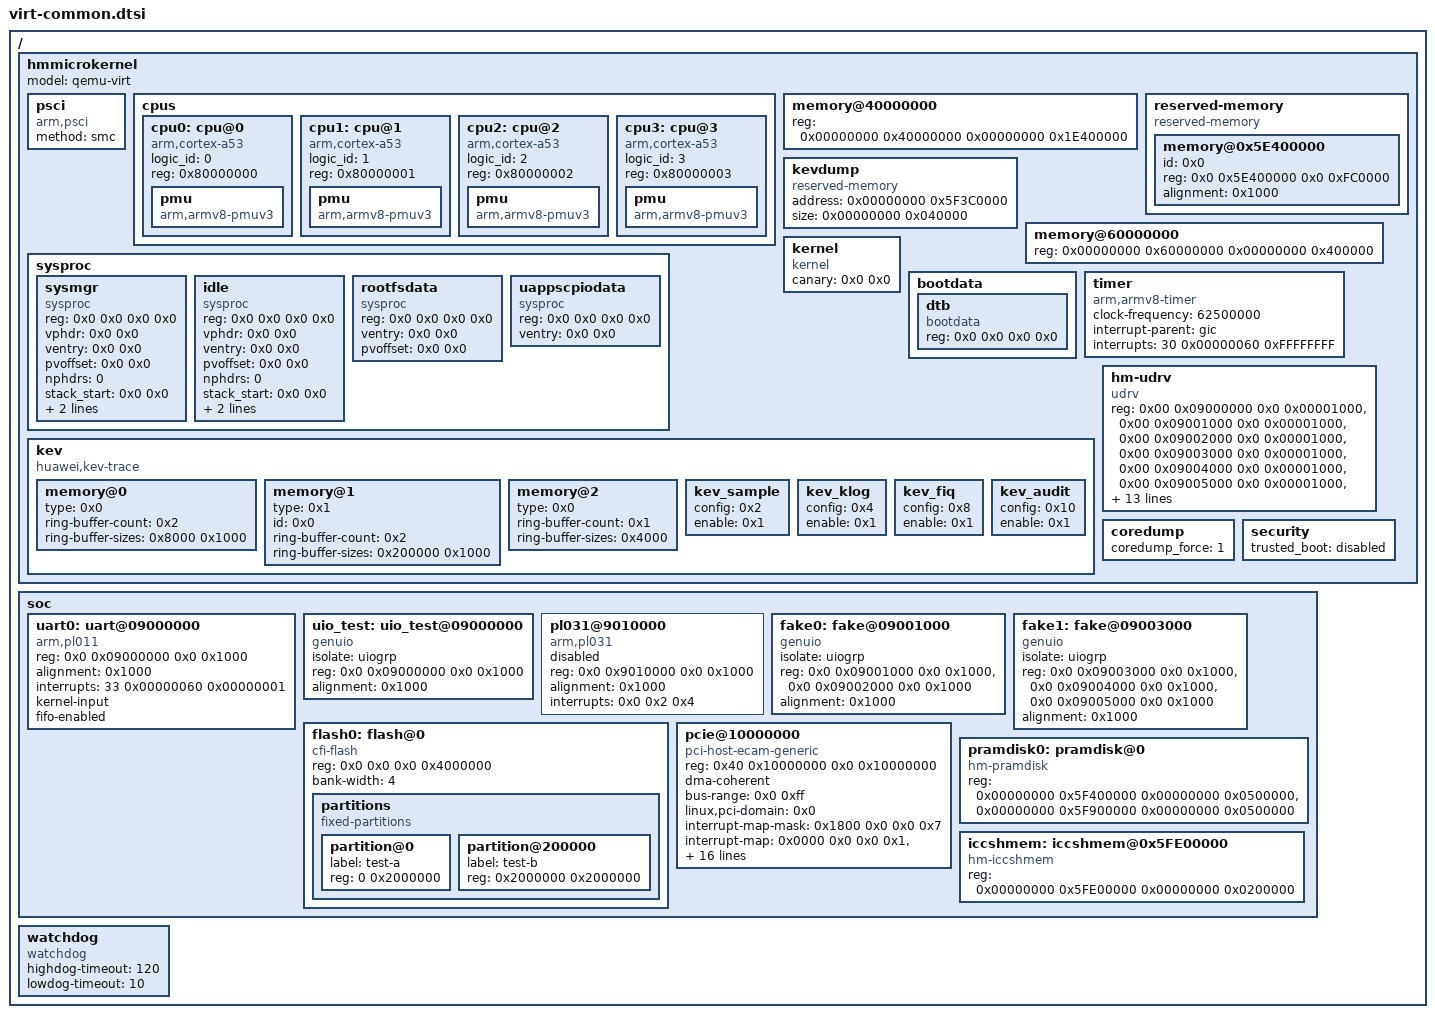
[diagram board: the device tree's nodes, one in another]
/ {
	hmmicrokernel {
		model = "qemu-virt";
		psci {
			compatible = "arm,psci";
			method = "smc";
		};

		cpus {
			#address-cells = <1>;
			#size-cells = <0>;
			cpu0: cpu@0 {
				compatible = "arm,cortex-a53", "arm,armv8";
				device_type = "cpu";
				logic_id = <0>;
				reg = <0x80000000>;
				pmu {
					compatible = "arm,armv8-pmuv3";
				};
			};
			cpu1: cpu@1 {
				compatible = "arm,cortex-a53", "arm,armv8";
				device_type = "cpu";
				logic_id = <1>;
				reg = <0x80000001>;
				pmu {
					compatible = "arm,armv8-pmuv3";
				};
			};
			cpu2: cpu@2 {
				compatible = "arm,cortex-a53", "arm,armv8";
				device_type = "cpu";
				logic_id = <2>;
				reg = <0x80000002>;
				pmu {
					compatible = "arm,armv8-pmuv3";
				};
			};
			cpu3: cpu@3 {
				compatible = "arm,cortex-a53", "arm,armv8";
				device_type = "cpu";
				logic_id = <3>;
				reg = <0x80000003>;
				pmu {
					compatible = "arm,armv8-pmuv3";
				};
			};
		};

		memory@40000000 {
			device_type = "memory";
			reg = <0x00000000 0x40000000 0x00000000 0x1E400000>;
		};

		reserved-memory {
			compatible = "reserved-memory";
			#address-cells = <2>;
			#size-cells = <2>;

			/* 16M - 256KB */
			memory@0x5E400000 {
				id = <0x0>;
				reg = <0x0 0x5E400000 0x0 0xFC0000>;
				alignment = <0x1000>;
			};
		};

		kevdump {
			compatible = "reserved-memory";
			address = <0x00000000 0x5F3C0000>;
			/* 256KB for kevdump */
			size = <0x00000000 0x040000>;
		};

		memory@60000000 {
			device_type = "memory";
			reg = <0x00000000 0x60000000 0x00000000 0x400000>;
		};

		sysproc {
			#address-cells = <2>;
			#size-cells = <2>;
			sysmgr {
				compatible = "sysproc", "sysmgr";
				/* filled by bootloader */
				reg      = <0x0 0x0 0x0 0x0>;
				vphdr    = <0x0 0x0>;
				ventry   = <0x0 0x0>;
				pvoffset = <0x0 0x0>;
				nphdrs   = <0>;
				stack_start = <0x0 0x0>;
				stack_end = <0x0 0x0>;
				canary = <0x0 0x0>;
			};
			idle {
				compatible = "sysproc", "idle";
				/* filled by bootloader */
				reg      = <0x0 0x0 0x0 0x0>;
				vphdr    = <0x0 0x0>;
				ventry   = <0x0 0x0>;
				pvoffset = <0x0 0x0>;
				nphdrs   = <0>;
				stack_start = <0x0 0x0>;
				stack_end = <0x0 0x0>;
				canary = <0x0 0x0>;
			};
			rootfsdata {
				compatible = "sysproc", "rootfs";
				/* filled by bootloader */
				reg      = <0x0 0x0 0x0 0x0>;
				ventry   = <0x0 0x0>;
				pvoffset = <0x0 0x0>;
			};
			uappscpiodata {
				compatible = "sysproc", "uappscpio";
				/* filled by bootloader */
				reg      = <0x0 0x0 0x0 0x0>;
				ventry   = <0x0 0x0>;
			};
		};

		kernel {
			compatible = "kernel";
			/* filled by bootloader */
			canary = <0x0 0x0>;
		};

		bootdata {
			#address-cells = <2>;
			#size-cells = <2>;
			dtb {
				compatible = "bootdata", "dtb";
				/* filled by bootloader */
				reg = <0x0 0x0 0x0 0x0>;
			};
		};

		timer {
			compatible = "arm,armv8-timer";
			clock-frequency = <62500000>;
			/* cnt value (ms) to trigger interrupt */
			/* interrupt settings */
			interrupt-parent = <&gic>;

			/* PPI 30: Non-secure physical timer
			 * level triggered, hwprio:0x60 */
			interrupts = <30 0x00000060 0xFFFFFFFF>;
		};

		kev {
			compatible = "huawei,kev-trace";

			memory@0 {
				type = <0x0>;
				ring-buffer-count = <0x2>;
				/*
				 * ring buffer 0: 32K (default)
				 * ring buffer 1: 4K (sample)
				 */
				ring-buffer-sizes = <0x8000 0x1000>;
			};

			memory@1 {
				type = <0x1>;
				id = <0x0>; /* reserved memory */
				ring-buffer-count = <0x2>;
				/*
				 * ring buffer 2: 2M (klog)
				 * ring buffer 3: 4k (fiq)
				 */
				ring-buffer-sizes = <0x200000 0x1000>;
			};

			memory@2 {
				type = <0x0>;
				ring-buffer-count = <0x1>;
				/*
				 * ring buffer 4: 16K (audit)
				 */
				ring-buffer-sizes = <0x4000>;
			};

			kev_sample {
				config = <0x2>;
				enable = <0x1>;
			};
			kev_klog {
				config = <0x4>;
				enable = <0x1>;
			};
			kev_fiq {
				config = <0x8>;
				enable = <0x1>;
			};
			kev_audit {
				config = <0x10>;
				enable = <0x1>;
			};
		};

		hm-udrv {
			compatible = "udrv";
			reg = <0x00 0x09000000 0x0 0x00001000>,
			      <0x00 0x09001000 0x0 0x00001000>,
			      <0x00 0x09002000 0x0 0x00001000>,
			      <0x00 0x09003000 0x0 0x00001000>,
			      <0x00 0x09004000 0x0 0x00001000>,
			      <0x00 0x09005000 0x0 0x00001000>,
			      <0x00 0x09010000 0x0 0x00001000>,
			      <0x00 0x0a000000 0x0 0x00004000>,
			      <0x00 0x00000000 0x0 0x04000000>,
			      <0x00 0x10000000 0x0 0x2eff0000>,	/* PCIE MMIO */
			      <0x00 0x3eff0000 0x0 0x00010000>,	/* PCIE PIO  */
			      <0x00 0x3f000000 0x0 0x01000000>,	/* PCIE ECAM */
			      <0x80 0x00000000 0x0 0x00004000>,
			      <0x00 0x5F3C0000 0x0 0x00040000>,	/* kevdump */
			      <0x00 0x5F400000 0x0 0x00500000>,
			      <0x00 0x5F900000 0x0 0x00500000>,
			      <0x00 0x5FE00000 0x0 0x00200000>,
			      <0x40 0x10000000 0x0 0x10000000>,	/* PCIE BAR */
			      <0x80 0x00000000 0x0 0x10000000>;
		};

		coredump {
			coredump_force = <1>;
		};

		security {
			trusted_boot = "disabled";
		};
	};

	soc {
		uart0: uart@09000000 {
			compatible = "arm,pl011","arm,pl011,uart";
			reg = <0x0 0x09000000 0x0 0x1000>;
			alignment = <0x1000>;

			interrupts = <33 0x00000060 0x00000001>;
			kernel-input;
			fifo-enabled;
		};

		uio_test: uio_test@09000000 {
			compatible = "genuio";
			isolate = "uiogrp";
			reg = <0x0 0x09000000 0x0 0x1000>;
			alignment = <0x1000>;
		};

		pl031@9010000 {
			compatible = "arm,pl031","arm,primecell";
			/* this device is for irq test, let devhost ignore it */
			status = "disabled";
			reg = <0x0 0x9010000 0x0 0x1000>;
			alignment = <0x1000>;
			interrupts = <0x0 0x2 0x4>;
		};

		/* fakedevice*2 for testcase "test__devmgr_multi_uio" */
		fake0: fake@09001000 {
			compatible = "genuio";
			isolate = "uiogrp";
			reg = <0x0 0x09001000 0x0 0x1000>,
			      <0x0 0x09002000 0x0 0x1000>;
			alignment = <0x1000>;
		};

		fake1: fake@09003000 {
			compatible = "genuio";
			isolate = "uiogrp";
			reg = <0x0 0x09003000 0x0 0x1000>,
			      <0x0 0x09004000 0x0 0x1000>,
			      <0x0 0x09005000 0x0 0x1000>;
			alignment = <0x1000>;
		};

		flash0: flash@0 {
			compatible = "cfi-flash";
			reg = <0x0 0x0 0x0 0x4000000>;
			bank-width = <4>;
			partitions {
				compatible = "fixed-partitions";
				#address-cells = <1>;
				#size-cells = <1>;
				partition@0 {
					label = "test-a";
					reg = <0 0x2000000>;
				};
				partition@200000 {
					label = "test-b";
					reg = <0x2000000 0x2000000>;
				};
			};
		};

		pcie@10000000 {
			#size-cells = <0x2>;
			#address-cells = <0x3>;
			#interrupt-cells = <0x1>;
			device_type = "pci";
			compatible = "pci-host-ecam-generic";
			reg = <0x40 0x10000000 0x0 0x10000000>;
			dma-coherent;
			ranges = <0x1000000 0x0 0x0 0x0 0x3eff0000 0x0 0x10000
				  0x2000000 0x0 0x10000000 0x0 0x10000000 0x0 0x2eff0000
				  0x3000000 0x80 0x0 0x80 0x0 0x80 0x0>;
			bus-range = <0x0 0xff>;
			linux,pci-domain = <0x0>;
			interrupt-map-mask = <0x1800 0x0 0x0 0x7>;
			interrupt-map = <0x0000 0x0 0x0 0x1 &gic 0x0 0x0 0x0 0x3 0x4
					 0x0000 0x0 0x0 0x2 &gic 0x0 0x0 0x0 0x4 0x4
					 0x0000 0x0 0x0 0x3 &gic 0x0 0x0 0x0 0x5 0x4
					 0x0000 0x0 0x0 0x4 &gic 0x0 0x0 0x0 0x6 0x4
					 0x0800 0x0 0x0 0x1 &gic 0x0 0x0 0x0 0x4 0x4
					 0x0800 0x0 0x0 0x2 &gic 0x0 0x0 0x0 0x5 0x4
					 0x0800 0x0 0x0 0x3 &gic 0x0 0x0 0x0 0x6 0x4
					 0x0800 0x0 0x0 0x4 &gic 0x0 0x0 0x0 0x3 0x4
					 0x1000 0x0 0x0 0x1 &gic 0x0 0x0 0x0 0x5 0x4
					 0x1000 0x0 0x0 0x2 &gic 0x0 0x0 0x0 0x6 0x4
					 0x1000 0x0 0x0 0x3 &gic 0x0 0x0 0x0 0x3 0x4
					 0x1000 0x0 0x0 0x4 &gic 0x0 0x0 0x0 0x4 0x4
					 0x1800 0x0 0x0 0x1 &gic 0x0 0x0 0x0 0x6 0x4
					 0x1800 0x0 0x0 0x2 &gic 0x0 0x0 0x0 0x3 0x4
					 0x1800 0x0 0x0 0x3 &gic 0x0 0x0 0x0 0x4 0x4
					 0x1800 0x0 0x0 0x4 &gic 0x0 0x0 0x0 0x5 0x4>;
		};

		/*
		* configuration for pramdisk, and two block devices
		* the size can be modified according to actual condition.
		*/
		pramdisk0: pramdisk@0 {
			compatible = "hm-pramdisk";
			reg = <0x00000000 0x5F400000 0x00000000 0x0500000>,
			      <0x00000000 0x5F900000 0x00000000 0x0500000>;
		};

		iccshmem: iccshmem@0x5FE00000 {
			compatible = "hm-iccshmem";
			reg = <0x00000000 0x5FE00000 0x00000000 0x0200000>;
		};
	};

	watchdog {
		compatible = "watchdog";
		/* reserve 120s for hguard to take over the watchdog */
		highdog-timeout = <120>;
		/* reserve 10s for subcore to be pulled up*/
		lowdog-timeout = <10>;
	};
};
